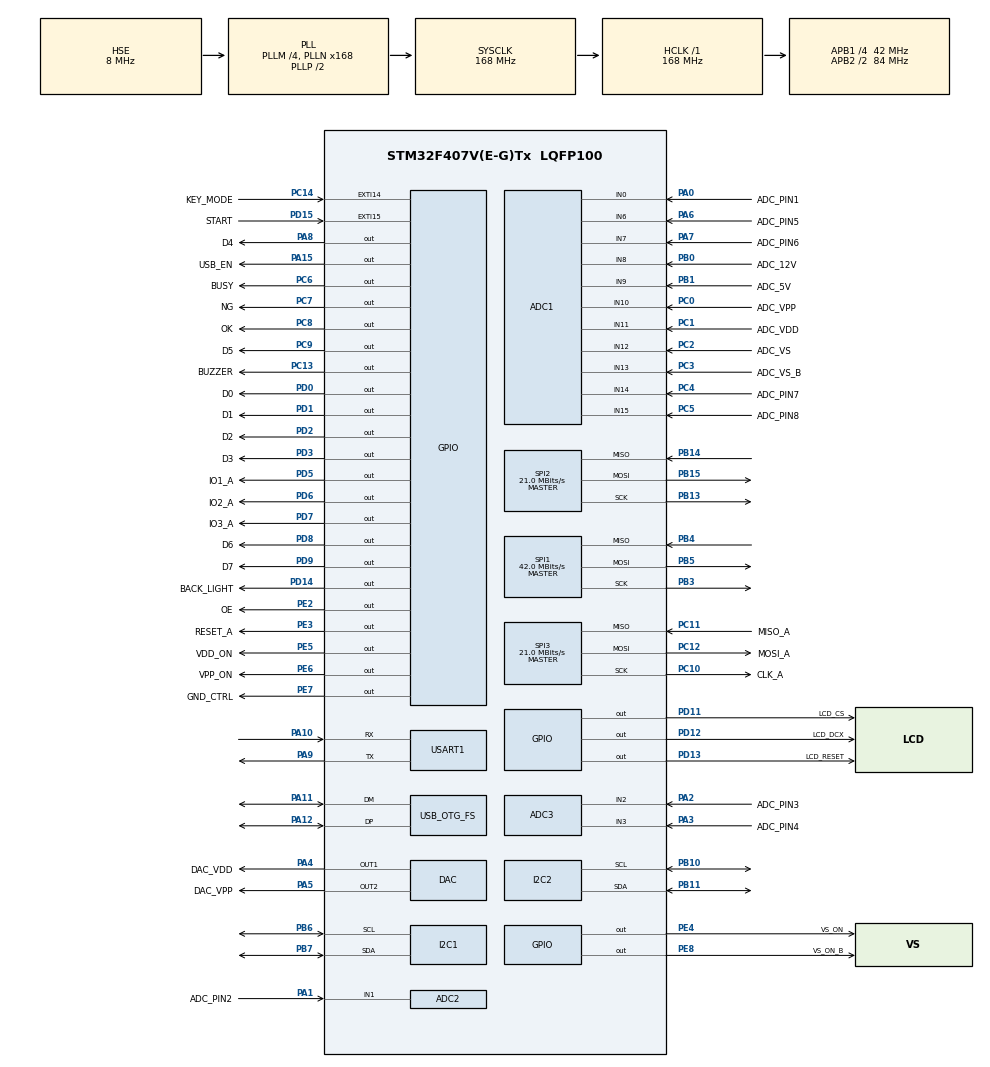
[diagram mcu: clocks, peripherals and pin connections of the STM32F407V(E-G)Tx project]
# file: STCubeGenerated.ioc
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ADC1.Channel-0\#ChannelRegularConversion=ADC_CHANNEL_0
ADC1.NbrOfConversionFlag=1
ADC1.Rank-0\#ChannelRegularConversion=1
ADC1.SamplingTime-0\#ChannelRegularConversion=ADC_SAMPLETIME_3CYCLES
ADC1.master=1
ADC2.Channel-0\#ChannelRegularConversion=ADC_CHANNEL_1
ADC2.NbrOfConversionFlag=1
ADC2.Rank-0\#ChannelRegularConversion=1
ADC2.SamplingTime-0\#ChannelRegularConversion=ADC_SAMPLETIME_3CYCLES
ADC3.Channel-0\#ChannelRegularConversion=ADC_CHANNEL_2
ADC3.NbrOfConversionFlag=1
ADC3.Rank-0\#ChannelRegularConversion=1
ADC3.SamplingTime-0\#ChannelRegularConversion=ADC_SAMPLETIME_3CYCLES
Mcu.Family=STM32F4
Mcu.Name=STM32F407V(E-G)Tx
Mcu.Package=LQFP100
NVIC.EXTI15_10_IRQn=true\:0\:0\:false\:false\:true\:true
NVIC.PriorityGroup=NVIC_PRIORITYGROUP_4
PA0-WKUP.GPIO_Label=ADC_PIN1
PA0-WKUP.Signal=ADCx_IN0
PA1.GPIO_Label=ADC_PIN2
PA1.Signal=ADCx_IN1
PA10.Mode=Asynchronous
PA10.Signal=USART1_RX
PA11.Mode=Device_Only
PA11.Signal=USB_OTG_FS_DM
PA12.Mode=Device_Only
PA12.Signal=USB_OTG_FS_DP
PA15.GPIO_Label=USB_EN
PA15.GPIO_PuPd=GPIO_PULLUP
PA15.PinState=GPIO_PIN_SET
PA15.Signal=GPIO_Output
PA2.GPIO_Label=ADC_PIN3
PA2.Signal=ADCx_IN2
PA3.GPIO_Label=ADC_PIN4
PA3.Signal=ADCx_IN3
PA4.GPIO_Label=DAC_VDD
PA4.Signal=COMP_DAC1_group
PA5.GPIO_Label=DAC_VPP
PA5.Signal=COMP_DAC2_group
PA6.GPIO_Label=ADC_PIN5
PA6.Signal=ADCx_IN6
PA7.GPIO_Label=ADC_PIN6
PA7.Signal=ADCx_IN7
PA8.GPIO_Label=D4
PA8.GPIO_PuPd=GPIO_PULLUP
PA8.Signal=GPIO_Output
PA9.Mode=Asynchronous
PA9.Signal=USART1_TX
PB0.GPIO_Label=ADC_12V
PB0.Signal=ADCx_IN8
PB1.GPIO_Label=ADC_5V
PB1.Signal=ADCx_IN9
PB10.Mode=I2C
PB10.Signal=I2C2_SCL
PB11.Mode=I2C
PB11.Signal=I2C2_SDA
PB12.Signal=SPI2_NSS
PB13.GPIO_PuPd=GPIO_NOPULL
PB13.Mode=Full_Duplex_Master
PB13.Signal=SPI2_SCK
PB14.Mode=Full_Duplex_Master
PB14.Signal=SPI2_MISO
PB15.GPIO_PuPd=GPIO_PULLUP
PB15.Mode=Full_Duplex_Master
PB15.Signal=SPI2_MOSI
PB3.Mode=Full_Duplex_Master
PB3.Signal=SPI1_SCK
PB4.Mode=Full_Duplex_Master
PB4.Signal=SPI1_MISO
PB5.Mode=Full_Duplex_Master
PB5.Signal=SPI1_MOSI
PB6.Mode=I2C
PB6.Signal=I2C1_SCL
PB7.Mode=I2C
PB7.Signal=I2C1_SDA
PC0.GPIO_Label=ADC_VPP
PC0.Signal=ADCx_IN10
PC1.GPIO_Label=ADC_VDD
PC1.Signal=ADCx_IN11
PC10.GPIO_Label=CLK_A
PC10.Mode=Full_Duplex_Master
PC10.Signal=SPI3_SCK
PC11.GPIO_Label=MISO_A
PC11.Mode=Full_Duplex_Master
PC11.Signal=SPI3_MISO
PC12.GPIO_Label=MOSI_A
PC12.Mode=Full_Duplex_Master
PC12.Signal=SPI3_MOSI
PC13-ANTI_TAMP.GPIO_Label=BUZZER
PC13-ANTI_TAMP.GPIO_PuPd=GPIO_PULLUP
PC13-ANTI_TAMP.Signal=GPIO_Output
PC14-OSC32_IN.GPIO_Label=KEY_MODE
PC14-OSC32_IN.GPIO_ModeDefaultEXTI=GPIO_MODE_IT_RISING_FALLING
PC14-OSC32_IN.GPIO_PuPd=GPIO_PULLDOWN
PC14-OSC32_IN.Signal=GPXTI14
PC2.GPIO_Label=ADC_VS
PC2.Signal=ADCx_IN12
PC3.GPIO_Label=ADC_VS_B
PC3.Signal=ADCx_IN13
PC4.GPIO_Label=ADC_PIN7
PC4.Signal=ADCx_IN14
PC5.GPIO_Label=ADC_PIN8
PC5.Signal=ADCx_IN15
PC6.GPIO_Label=BUSY
PC6.GPIO_PuPd=GPIO_PULLDOWN
PC6.Signal=GPIO_Output
PC7.GPIO_Label=NG
PC7.GPIO_PuPd=GPIO_PULLDOWN
PC7.Signal=GPIO_Output
PC8.GPIO_Label=OK
PC8.GPIO_PuPd=GPIO_PULLDOWN
PC8.Signal=GPIO_Output
PC9.GPIO_Label=D5
PC9.GPIO_PuPd=GPIO_PULLUP
PC9.Signal=GPIO_Output
PD0.GPIO_Label=D0
PD0.GPIO_PuPd=GPIO_PULLUP
PD0.Signal=GPIO_Output
PD1.GPIO_Label=D1
PD1.GPIO_PuPd=GPIO_PULLUP
PD1.Signal=GPIO_Output
PD11.GPIO_Label=LCD_CS
PD11.GPIO_PuPd=GPIO_PULLUP
PD11.PinState=GPIO_PIN_SET
PD11.Signal=GPIO_Output
PD12.GPIO_Label=LCD_DCX
PD12.GPIO_PuPd=GPIO_PULLUP
PD12.Signal=GPIO_Output
PD13.GPIO_Label=LCD_RESET
PD13.GPIO_PuPd=GPIO_PULLUP
PD13.PinState=GPIO_PIN_SET
PD13.Signal=GPIO_Output
PD14.GPIO_Label=BACK_LIGHT
PD14.GPIO_PuPd=GPIO_PULLUP
PD14.Signal=GPIO_Output
PD15.GPIO_Label=START
PD15.GPIO_ModeDefaultEXTI=GPIO_MODE_IT_RISING_FALLING
PD15.GPIO_PuPd=GPIO_PULLUP
PD15.Signal=GPXTI15
PD2.GPIO_Label=D2
PD2.GPIO_PuPd=GPIO_PULLUP
PD2.Signal=GPIO_Output
PD3.GPIO_Label=D3
PD3.GPIO_PuPd=GPIO_PULLUP
PD3.Signal=GPIO_Output
PD5.GPIO_Label=IO1_A
PD5.GPIO_PuPd=GPIO_PULLUP
PD5.Signal=GPIO_Output
PD6.GPIO_Label=IO2_A
PD6.GPIO_PuPd=GPIO_PULLUP
PD6.Signal=GPIO_Output
PD7.GPIO_Label=IO3_A
PD7.GPIO_PuPd=GPIO_PULLUP
PD7.Signal=GPIO_Output
PD8.GPIO_Label=D6
PD8.GPIO_PuPd=GPIO_PULLUP
PD8.Signal=GPIO_Output
PD9.GPIO_Label=D7
PD9.GPIO_PuPd=GPIO_PULLUP
PD9.Signal=GPIO_Output
PE2.GPIO_Label=OE
PE2.GPIO_PuPd=GPIO_PULLUP
PE2.Signal=GPIO_Output
PE3.GPIO_Label=RESET_A
PE3.GPIO_PuPd=GPIO_PULLUP
PE3.Signal=GPIO_Output
PE4.GPIO_Label=VS_ON
PE4.GPIO_PuPd=GPIO_PULLUP
PE4.Signal=GPIO_Output
PE5.GPIO_Label=VDD_ON
PE5.GPIO_PuPd=GPIO_PULLUP
PE5.Signal=GPIO_Output
PE6.GPIO_Label=VPP_ON
PE6.GPIO_PuPd=GPIO_PULLUP
PE6.Signal=GPIO_Output
PE7.GPIO_Label=GND_CTRL
PE7.GPIO_PuPd=GPIO_PULLUP
PE7.GPIO_Speed=GPIO_SPEED_FREQ_LOW
PE7.PinState=GPIO_PIN_SET
PE7.Signal=GPIO_Output
PE8.GPIO_Label=VS_ON_B
PE8.GPIO_PuPd=GPIO_PULLUP
PE8.Signal=GPIO_Output
PH0-OSC_IN.Mode=HSE-External-Oscillator
PH0-OSC_IN.Signal=RCC_OSC_IN
PH1-OSC_OUT.Mode=HSE-External-Oscillator
PH1-OSC_OUT.Signal=RCC_OSC_OUT
ProjectManager.HeapSize=0x8000
ProjectManager.StackSize=0x8000
ProjectManager.TargetToolchain=MDK-ARM V5
RCC.48MHZClocksFreq_Value=48000000
RCC.AHBFreq_Value=168000000
RCC.APB1CLKDivider=RCC_HCLK_DIV4
RCC.APB1Freq_Value=42000000
RCC.APB1TimFreq_Value=84000000
RCC.APB2CLKDivider=RCC_HCLK_DIV2
RCC.APB2Freq_Value=84000000
RCC.APB2TimFreq_Value=168000000
RCC.CortexFreq_Value=168000000
RCC.HCLKFreq_Value=168000000
RCC.HSE_VALUE=8000000
RCC.HSI_VALUE=16000000
RCC.LSE_VALUE=32768
RCC.PLLM=4
RCC.PLLN=168
RCC.PLLQ=7
RCC.SYSCLKFreq_VALUE=168000000
RCC.SYSCLKSource=RCC_SYSCLKSOURCE_PLLCLK
RCC.VCOOutputFreq_Value=336000000
SH.ADCx_IN0.0=ADC1_IN0,IN0
SH.ADCx_IN1.0=ADC2_IN1,IN1
SH.ADCx_IN10.0=ADC1_IN10,IN10
SH.ADCx_IN11.0=ADC1_IN11,IN11
SH.ADCx_IN12.0=ADC1_IN12,IN12
SH.ADCx_IN13.0=ADC1_IN13,IN13
SH.ADCx_IN14.0=ADC1_IN14,IN14
SH.ADCx_IN15.0=ADC1_IN15,IN15
SH.ADCx_IN2.0=ADC3_IN2,IN2
SH.ADCx_IN3.0=ADC3_IN3,IN3
SH.ADCx_IN6.0=ADC1_IN6,IN6
SH.ADCx_IN7.0=ADC1_IN7,IN7
SH.ADCx_IN8.0=ADC1_IN8,IN8
SH.ADCx_IN9.0=ADC1_IN9,IN9
SH.COMP_DAC1_group.0=DAC_OUT1,DAC_OUT1
SH.COMP_DAC2_group.0=DAC_OUT2,DAC_OUT2
SPI1.CalculateBaudRate=42.0 MBits/s
SPI1.Direction=SPI_DIRECTION_2LINES
SPI1.Mode=SPI_MODE_MASTER
SPI1.VirtualType=VM_MASTER
SPI2.CalculateBaudRate=21.0 MBits/s
SPI2.Direction=SPI_DIRECTION_2LINES
SPI2.Mode=SPI_MODE_MASTER
SPI2.VirtualType=VM_MASTER
SPI3.CalculateBaudRate=21.0 MBits/s
SPI3.Direction=SPI_DIRECTION_2LINES
SPI3.Mode=SPI_MODE_MASTER
SPI3.VirtualType=VM_MASTER
TIM13.ClockDivision=TIM_CLOCKDIVISION_DIV1
TIM13.Prescaler=0xa410
TIM6.Prescaler=0x54
TIM7.Prescaler=0x54
USART1.VirtualMode=VM_ASYNC
USB_OTG_FS.VirtualMode=Device_Only
VP_CRC_VS_CRC.Mode=CRC_Activate
VP_TIM10_VS_ClockSourceINT.Mode=Enable_Timer
VP_TIM13_VS_ClockSourceINT.Mode=Enable_Timer
VP_TIM14_VS_ClockSourceINT.Mode=Enable_Timer
VP_TIM6_VS_ClockSourceINT.Mode=Enable_Timer
VP_TIM7_VS_ClockSourceINT.Mode=Enable_Timer
board=custom

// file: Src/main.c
/**
  ******************************************************************************
  * @file           : main.c
  * @brief          : Main program body
  ******************************************************************************
  ** This notice applies to any and all portions of this file
  * that are not between comment pairs USER CODE BEGIN and
  * USER CODE END. Other portions of this file, whether
  * inserted by the user or by software development tools
  * are owned by their respective copyright owners.
  *
  * COPYRIGHT(c) 2019 STMicroelectronics
  *
  * Redistribution and use in source and binary forms, with or without modification,
  * are permitted provided that the following conditions are met:
  *   1. Redistributions of source code must retain the above copyright notice,
  *      this list of conditions and the following disclaimer.
  *   2. Redistributions in binary form must reproduce the above copyright notice,
  *      this list of conditions and the following disclaimer in the documentation
  *      and/or other materials provided with the distribution.
  *   3. Neither the name of STMicroelectronics nor the names of its contributors
  *      may be used to endorse or promote products derived from this software
  *      without specific prior written permission.
  *
  * THIS SOFTWARE IS PROVIDED BY THE COPYRIGHT HOLDERS AND CONTRIBUTORS "AS IS"
  * AND ANY EXPRESS OR IMPLIED WARRANTIES, INCLUDING, BUT NOT LIMITED TO, THE
  * IMPLIED WARRANTIES OF MERCHANTABILITY AND FITNESS FOR A PARTICULAR PURPOSE ARE
  * DISCLAIMED. IN NO EVENT SHALL THE COPYRIGHT HOLDER OR CONTRIBUTORS BE LIABLE
  * FOR ANY DIRECT, INDIRECT, INCIDENTAL, SPECIAL, EXEMPLARY, OR CONSEQUENTIAL
  * DAMAGES (INCLUDING, BUT NOT LIMITED TO, PROCUREMENT OF SUBSTITUTE GOODS OR
  * SERVICES; LOSS OF USE, DATA, OR PROFITS; OR BUSINESS INTERRUPTION) HOWEVER
  * CAUSED AND ON ANY THEORY OF LIABILITY, WHETHER IN CONTRACT, STRICT LIABILITY,
  * OR TORT (INCLUDING NEGLIGENCE OR OTHERWISE) ARISING IN ANY WAY OUT OF THE USE
  * OF THIS SOFTWARE, EVEN IF ADVISED OF THE POSSIBILITY OF SUCH DAMAGE.
  *
  ******************************************************************************
  */
#include "main.h"
#include "stm32f4xx_hal.h"

/* USER CODE BEGIN Includes */
#include "bootloader.h"
/* USER CODE END Includes */

ADC_HandleTypeDef hadc1;
ADC_HandleTypeDef hadc2;
ADC_HandleTypeDef hadc3;

CRC_HandleTypeDef hcrc;

DAC_HandleTypeDef hdac;

I2C_HandleTypeDef hi2c1;
I2C_HandleTypeDef hi2c2;

SPI_HandleTypeDef hspi1;
SPI_HandleTypeDef hspi2;
SPI_HandleTypeDef hspi3;

TIM_HandleTypeDef htim6;
TIM_HandleTypeDef htim7;
TIM_HandleTypeDef htim10;
TIM_HandleTypeDef htim13;
TIM_HandleTypeDef htim14;

UART_HandleTypeDef huart1;

PCD_HandleTypeDef hpcd_USB_OTG_FS;

/* USER CODE BEGIN PV */
/* Private variables ---------------------------------------------------------*/

/* USER CODE END PV */

void SystemClock_Config(void);
static void MX_GPIO_Init(void);
static void MX_USB_OTG_FS_PCD_Init(void);
static void MX_USART1_UART_Init(void);
static void MX_ADC1_Init(void);
static void MX_ADC2_Init(void);
static void MX_ADC3_Init(void);
static void MX_DAC_Init(void);
static void MX_CRC_Init(void);
static void MX_SPI2_Init(void);
static void MX_I2C2_Init(void);
static void MX_I2C1_Init(void);
static void MX_SPI1_Init(void);
static void MX_SPI3_Init(void);
static void MX_TIM6_Init(void);
static void MX_TIM7_Init(void);
static void MX_TIM10_Init(void);
static void MX_TIM13_Init(void);
static void MX_TIM14_Init(void);

/* USER CODE BEGIN PFP */
/* Private function prototypes -----------------------------------------------*/

/* USER CODE END PFP */

int main(void)
{

  /* MCU Configuration----------------------------------------------------------*/

  /* Reset of all peripherals, Initializes the Flash interface and the Systick. */
  HAL_Init();

  /* Configure the system clock */
  SystemClock_Config();

  /* Initialize all configured peripherals */
  MX_GPIO_Init();
  MX_USB_OTG_FS_PCD_Init();
  MX_USART1_UART_Init();
  MX_ADC1_Init();
  MX_ADC2_Init();
  MX_ADC3_Init();
  MX_DAC_Init();
  MX_CRC_Init();
  MX_SPI2_Init();
  MX_I2C2_Init();
  MX_I2C1_Init();
  MX_SPI1_Init();
  MX_SPI3_Init();
  MX_TIM6_Init();
  MX_TIM7_Init();
  MX_TIM10_Init();
  MX_TIM13_Init();
  MX_TIM14_Init();
  /* USER CODE BEGIN 2 */
	osStart();
  /* USER CODE END 2 */

  /* Infinite loop */
  while (1)
  {

  }

}

void SystemClock_Config(void)
{

  RCC_OscInitTypeDef RCC_OscInitStruct;
  RCC_ClkInitTypeDef RCC_ClkInitStruct;

    /**Configure the main internal regulator output voltage
    */
  __HAL_RCC_PWR_CLK_ENABLE();

  __HAL_PWR_VOLTAGESCALING_CONFIG(PWR_REGULATOR_VOLTAGE_SCALE1);

    /**Initializes the CPU, AHB and APB busses clocks
    */
  RCC_OscInitStruct.OscillatorType = RCC_OSCILLATORTYPE_HSE;
  RCC_OscInitStruct.HSEState = RCC_HSE_ON;
  RCC_OscInitStruct.PLL.PLLState = RCC_PLL_ON;
  RCC_OscInitStruct.PLL.PLLSource = RCC_PLLSOURCE_HSE;
  RCC_OscInitStruct.PLL.PLLM = 4;
  RCC_OscInitStruct.PLL.PLLN = 168;
  RCC_OscInitStruct.PLL.PLLP = RCC_PLLP_DIV2;
  RCC_OscInitStruct.PLL.PLLQ = 7;
  if (HAL_RCC_OscConfig(&RCC_OscInitStruct) != HAL_OK)
  {
    _Error_Handler(__FILE__, __LINE__);
  }

    /**Initializes the CPU, AHB and APB busses clocks
    */
  RCC_ClkInitStruct.ClockType = RCC_CLOCKTYPE_HCLK|RCC_CLOCKTYPE_SYSCLK
                              |RCC_CLOCKTYPE_PCLK1|RCC_CLOCKTYPE_PCLK2;
  RCC_ClkInitStruct.SYSCLKSource = RCC_SYSCLKSOURCE_PLLCLK;
  RCC_ClkInitStruct.AHBCLKDivider = RCC_SYSCLK_DIV1;
  RCC_ClkInitStruct.APB1CLKDivider = RCC_HCLK_DIV4;
  RCC_ClkInitStruct.APB2CLKDivider = RCC_HCLK_DIV2;

  if (HAL_RCC_ClockConfig(&RCC_ClkInitStruct, FLASH_LATENCY_5) != HAL_OK)
  {
    _Error_Handler(__FILE__, __LINE__);
  }

    /**Configure the Systick interrupt time
    */
  HAL_SYSTICK_Config(HAL_RCC_GetHCLKFreq()/1000);

    /**Configure the Systick
    */
  HAL_SYSTICK_CLKSourceConfig(SYSTICK_CLKSOURCE_HCLK);

  /* SysTick_IRQn interrupt configuration */
  HAL_NVIC_SetPriority(SysTick_IRQn, 0, 0);
}

/* ADC1 init function */
static void MX_ADC1_Init(void)
{

  ADC_ChannelConfTypeDef sConfig;

    /**Configure the global features of the ADC (Clock, Resolution, Data Alignment and number of conversion)
    */
  hadc1.Instance = ADC1;
  hadc1.Init.ClockPrescaler = ADC_CLOCK_SYNC_PCLK_DIV4;
  hadc1.Init.Resolution = ADC_RESOLUTION_12B;
  hadc1.Init.ScanConvMode = DISABLE;
  hadc1.Init.ContinuousConvMode = DISABLE;
  hadc1.Init.DiscontinuousConvMode = DISABLE;
  hadc1.Init.ExternalTrigConvEdge = ADC_EXTERNALTRIGCONVEDGE_NONE;
  hadc1.Init.ExternalTrigConv = ADC_SOFTWARE_START;
  hadc1.Init.DataAlign = ADC_DATAALIGN_RIGHT;
  hadc1.Init.NbrOfConversion = 1;
  hadc1.Init.DMAContinuousRequests = DISABLE;
  hadc1.Init.EOCSelection = ADC_EOC_SINGLE_CONV;
  if (HAL_ADC_Init(&hadc1) != HAL_OK)
  {
    _Error_Handler(__FILE__, __LINE__);
  }

    /**Configure for the selected ADC regular channel its corresponding rank in the sequencer and its sample time.
    */
  sConfig.Channel = ADC_CHANNEL_0;
  sConfig.Rank = 1;
  sConfig.SamplingTime = ADC_SAMPLETIME_3CYCLES;
  if (HAL_ADC_ConfigChannel(&hadc1, &sConfig) != HAL_OK)
  {
    _Error_Handler(__FILE__, __LINE__);
  }

}

/* ADC2 init function */
static void MX_ADC2_Init(void)
{

  ADC_ChannelConfTypeDef sConfig;

    /**Configure the global features of the ADC (Clock, Resolution, Data Alignment and number of conversion)
    */
  hadc2.Instance = ADC2;
  hadc2.Init.ClockPrescaler = ADC_CLOCK_SYNC_PCLK_DIV4;
  hadc2.Init.Resolution = ADC_RESOLUTION_12B;
  hadc2.Init.ScanConvMode = DISABLE;
  hadc2.Init.ContinuousConvMode = DISABLE;
  hadc2.Init.DiscontinuousConvMode = DISABLE;
  hadc2.Init.ExternalTrigConvEdge = ADC_EXTERNALTRIGCONVEDGE_NONE;
  hadc2.Init.ExternalTrigConv = ADC_SOFTWARE_START;
  hadc2.Init.DataAlign = ADC_DATAALIGN_RIGHT;
  hadc2.Init.NbrOfConversion = 1;
  hadc2.Init.DMAContinuousRequests = DISABLE;
  hadc2.Init.EOCSelection = ADC_EOC_SINGLE_CONV;
  if (HAL_ADC_Init(&hadc2) != HAL_OK)
  {
    _Error_Handler(__FILE__, __LINE__);
  }

    /**Configure for the selected ADC regular channel its corresponding rank in the sequencer and its sample time.
    */
  sConfig.Channel = ADC_CHANNEL_1;
  sConfig.Rank = 1;
  sConfig.SamplingTime = ADC_SAMPLETIME_3CYCLES;
  if (HAL_ADC_ConfigChannel(&hadc2, &sConfig) != HAL_OK)
  {
    _Error_Handler(__FILE__, __LINE__);
  }

}

/* ADC3 init function */
static void MX_ADC3_Init(void)
{

  ADC_ChannelConfTypeDef sConfig;

    /**Configure the global features of the ADC (Clock, Resolution, Data Alignment and number of conversion)
    */
  hadc3.Instance = ADC3;
  hadc3.Init.ClockPrescaler = ADC_CLOCK_SYNC_PCLK_DIV4;
  hadc3.Init.Resolution = ADC_RESOLUTION_12B;
  hadc3.Init.ScanConvMode = DISABLE;
  hadc3.Init.ContinuousConvMode = DISABLE;
  hadc3.Init.DiscontinuousConvMode = DISABLE;
  hadc3.Init.ExternalTrigConvEdge = ADC_EXTERNALTRIGCONVEDGE_NONE;
  hadc3.Init.ExternalTrigConv = ADC_SOFTWARE_START;
  hadc3.Init.DataAlign = ADC_DATAALIGN_RIGHT;
  hadc3.Init.NbrOfConversion = 1;
  hadc3.Init.DMAContinuousRequests = DISABLE;
  hadc3.Init.EOCSelection = ADC_EOC_SINGLE_CONV;
  if (HAL_ADC_Init(&hadc3) != HAL_OK)
  {
    _Error_Handler(__FILE__, __LINE__);
  }

    /**Configure for the selected ADC regular channel its corresponding rank in the sequencer and its sample time.
    */
  sConfig.Channel = ADC_CHANNEL_2;
  sConfig.Rank = 1;
  sConfig.SamplingTime = ADC_SAMPLETIME_3CYCLES;
  if (HAL_ADC_ConfigChannel(&hadc3, &sConfig) != HAL_OK)
  {
    _Error_Handler(__FILE__, __LINE__);
  }

}

/* CRC init function */
static void MX_CRC_Init(void)
{

  hcrc.Instance = CRC;
  if (HAL_CRC_Init(&hcrc) != HAL_OK)
  {
    _Error_Handler(__FILE__, __LINE__);
  }

}

/* DAC init function */
static void MX_DAC_Init(void)
{

  DAC_ChannelConfTypeDef sConfig;

    /**DAC Initialization
    */
  hdac.Instance = DAC;
  if (HAL_DAC_Init(&hdac) != HAL_OK)
  {
    _Error_Handler(__FILE__, __LINE__);
  }

    /**DAC channel OUT1 config
    */
  sConfig.DAC_Trigger = DAC_TRIGGER_NONE;
  sConfig.DAC_OutputBuffer = DAC_OUTPUTBUFFER_ENABLE;
  if (HAL_DAC_ConfigChannel(&hdac, &sConfig, DAC_CHANNEL_1) != HAL_OK)
  {
    _Error_Handler(__FILE__, __LINE__);
  }

    /**DAC channel OUT2 config
    */
  if (HAL_DAC_ConfigChannel(&hdac, &sConfig, DAC_CHANNEL_2) != HAL_OK)
  {
    _Error_Handler(__FILE__, __LINE__);
  }

}

/* I2C1 init function */
static void MX_I2C1_Init(void)
{

  hi2c1.Instance = I2C1;
  hi2c1.Init.ClockSpeed = 100000;
  hi2c1.Init.DutyCycle = I2C_DUTYCYCLE_2;
  hi2c1.Init.OwnAddress1 = 0;
  hi2c1.Init.AddressingMode = I2C_ADDRESSINGMODE_7BIT;
  hi2c1.Init.DualAddressMode = I2C_DUALADDRESS_DISABLE;
  hi2c1.Init.OwnAddress2 = 0;
  hi2c1.Init.GeneralCallMode = I2C_GENERALCALL_DISABLE;
  hi2c1.Init.NoStretchMode = I2C_NOSTRETCH_DISABLE;
  if (HAL_I2C_Init(&hi2c1) != HAL_OK)
  {
    _Error_Handler(__FILE__, __LINE__);
  }

}

/* I2C2 init function */
static void MX_I2C2_Init(void)
{

  hi2c2.Instance = I2C2;
  hi2c2.Init.ClockSpeed = 100000;
  hi2c2.Init.DutyCycle = I2C_DUTYCYCLE_2;
  hi2c2.Init.OwnAddress1 = 0;
  hi2c2.Init.AddressingMode = I2C_ADDRESSINGMODE_7BIT;
  hi2c2.Init.DualAddressMode = I2C_DUALADDRESS_DISABLE;
  hi2c2.Init.OwnAddress2 = 0;
  hi2c2.Init.GeneralCallMode = I2C_GENERALCALL_DISABLE;
  hi2c2.Init.NoStretchMode = I2C_NOSTRETCH_DISABLE;
  if (HAL_I2C_Init(&hi2c2) != HAL_OK)
  {
    _Error_Handler(__FILE__, __LINE__);
  }

}

/* SPI1 init function */
static void MX_SPI1_Init(void)
{

  /* SPI1 parameter configuration*/
  hspi1.Instance = SPI1;
  hspi1.Init.Mode = SPI_MODE_MASTER;
  hspi1.Init.Direction = SPI_DIRECTION_2LINES;
  hspi1.Init.DataSize = SPI_DATASIZE_8BIT;
  hspi1.Init.CLKPolarity = SPI_POLARITY_LOW;
  hspi1.Init.CLKPhase = SPI_PHASE_1EDGE;
  hspi1.Init.NSS = SPI_NSS_SOFT;
  hspi1.Init.BaudRatePrescaler = SPI_BAUDRATEPRESCALER_2;
  hspi1.Init.FirstBit = SPI_FIRSTBIT_MSB;
  hspi1.Init.TIMode = SPI_TIMODE_DISABLE;
  hspi1.Init.CRCCalculation = SPI_CRCCALCULATION_DISABLE;
  hspi1.Init.CRCPolynomial = 10;
  if (HAL_SPI_Init(&hspi1) != HAL_OK)
  {
    _Error_Handler(__FILE__, __LINE__);
  }

}

/* SPI2 init function */
static void MX_SPI2_Init(void)
{

  /* SPI2 parameter configuration*/
  hspi2.Instance = SPI2;
  hspi2.Init.Mode = SPI_MODE_MASTER;
  hspi2.Init.Direction = SPI_DIRECTION_2LINES;
  hspi2.Init.DataSize = SPI_DATASIZE_8BIT;
  hspi2.Init.CLKPolarity = SPI_POLARITY_LOW;
  hspi2.Init.CLKPhase = SPI_PHASE_1EDGE;
  hspi2.Init.NSS = SPI_NSS_SOFT;
  hspi2.Init.BaudRatePrescaler = SPI_BAUDRATEPRESCALER_2;
  hspi2.Init.FirstBit = SPI_FIRSTBIT_MSB;
  hspi2.Init.TIMode = SPI_TIMODE_DISABLE;
  hspi2.Init.CRCCalculation = SPI_CRCCALCULATION_DISABLE;
  hspi2.Init.CRCPolynomial = 10;
  if (HAL_SPI_Init(&hspi2) != HAL_OK)
  {
    _Error_Handler(__FILE__, __LINE__);
  }

}

/* SPI3 init function */
static void MX_SPI3_Init(void)
{

  /* SPI3 parameter configuration*/
  hspi3.Instance = SPI3;
  hspi3.Init.Mode = SPI_MODE_MASTER;
  hspi3.Init.Direction = SPI_DIRECTION_2LINES;
  hspi3.Init.DataSize = SPI_DATASIZE_8BIT;
  hspi3.Init.CLKPolarity = SPI_POLARITY_LOW;
  hspi3.Init.CLKPhase = SPI_PHASE_1EDGE;
  hspi3.Init.NSS = SPI_NSS_SOFT;
  hspi3.Init.BaudRatePrescaler = SPI_BAUDRATEPRESCALER_2;
  hspi3.Init.FirstBit = SPI_FIRSTBIT_MSB;
  hspi3.Init.TIMode = SPI_TIMODE_DISABLE;
  hspi3.Init.CRCCalculation = SPI_CRCCALCULATION_DISABLE;
  hspi3.Init.CRCPolynomial = 10;
  if (HAL_SPI_Init(&hspi3) != HAL_OK)
  {
    _Error_Handler(__FILE__, __LINE__);
  }

}

/* TIM6 init function */
static void MX_TIM6_Init(void)
{

  TIM_MasterConfigTypeDef sMasterConfig;

  htim6.Instance = TIM6;
  htim6.Init.Prescaler = 0x54;
  htim6.Init.CounterMode = TIM_COUNTERMODE_UP;
  htim6.Init.Period = 0;
  if (HAL_TIM_Base_Init(&htim6) != HAL_OK)
  {
    _Error_Handler(__FILE__, __LINE__);
  }

  sMasterConfig.MasterOutputTrigger = TIM_TRGO_RESET;
  sMasterConfig.MasterSlaveMode = TIM_MASTERSLAVEMODE_DISABLE;
  if (HAL_TIMEx_MasterConfigSynchronization(&htim6, &sMasterConfig) != HAL_OK)
  {
    _Error_Handler(__FILE__, __LINE__);
  }

}

/* TIM7 init function */
static void MX_TIM7_Init(void)
{

  TIM_MasterConfigTypeDef sMasterConfig;

  htim7.Instance = TIM7;
  htim7.Init.Prescaler = 0x54;
  htim7.Init.CounterMode = TIM_COUNTERMODE_UP;
  htim7.Init.Period = 0;
  if (HAL_TIM_Base_Init(&htim7) != HAL_OK)
  {
    _Error_Handler(__FILE__, __LINE__);
  }

  sMasterConfig.MasterOutputTrigger = TIM_TRGO_RESET;
  sMasterConfig.MasterSlaveMode = TIM_MASTERSLAVEMODE_DISABLE;
  if (HAL_TIMEx_MasterConfigSynchronization(&htim7, &sMasterConfig) != HAL_OK)
  {
    _Error_Handler(__FILE__, __LINE__);
  }

}

/* TIM10 init function */
static void MX_TIM10_Init(void)
{

  htim10.Instance = TIM10;
  htim10.Init.Prescaler = 0;
  htim10.Init.CounterMode = TIM_COUNTERMODE_UP;
  htim10.Init.Period = 0;
  htim10.Init.ClockDivision = TIM_CLOCKDIVISION_DIV1;
  if (HAL_TIM_Base_Init(&htim10) != HAL_OK)
  {
    _Error_Handler(__FILE__, __LINE__);
  }

}

/* TIM13 init function */
static void MX_TIM13_Init(void)
{

  htim13.Instance = TIM13;
  htim13.Init.Prescaler = 0xa410;
  htim13.Init.CounterMode = TIM_COUNTERMODE_UP;
  htim13.Init.Period = 0;
  htim13.Init.ClockDivision = TIM_CLOCKDIVISION_DIV1;
  if (HAL_TIM_Base_Init(&htim13) != HAL_OK)
  {
    _Error_Handler(__FILE__, __LINE__);
  }

}

/* TIM14 init function */
static void MX_TIM14_Init(void)
{

  htim14.Instance = TIM14;
  htim14.Init.Prescaler = 0;
  htim14.Init.CounterMode = TIM_COUNTERMODE_UP;
  htim14.Init.Period = 0;
  htim14.Init.ClockDivision = TIM_CLOCKDIVISION_DIV1;
  if (HAL_TIM_Base_Init(&htim14) != HAL_OK)
  {
    _Error_Handler(__FILE__, __LINE__);
  }

}

/* USART1 init function */
static void MX_USART1_UART_Init(void)
{

  huart1.Instance = USART1;
  huart1.Init.BaudRate = 115200;
  huart1.Init.WordLength = UART_WORDLENGTH_8B;
  huart1.Init.StopBits = UART_STOPBITS_1;
  huart1.Init.Parity = UART_PARITY_NONE;
  huart1.Init.Mode = UART_MODE_TX_RX;
  huart1.Init.HwFlowCtl = UART_HWCONTROL_NONE;
  huart1.Init.OverSampling = UART_OVERSAMPLING_16;
  if (HAL_UART_Init(&huart1) != HAL_OK)
  {
    _Error_Handler(__FILE__, __LINE__);
  }

}

/* USB_OTG_FS init function */
static void MX_USB_OTG_FS_PCD_Init(void)
{

  hpcd_USB_OTG_FS.Instance = USB_OTG_FS;
  hpcd_USB_OTG_FS.Init.dev_endpoints = 4;
  hpcd_USB_OTG_FS.Init.speed = PCD_SPEED_FULL;
  hpcd_USB_OTG_FS.Init.dma_enable = DISABLE;
  hpcd_USB_OTG_FS.Init.ep0_mps = DEP0CTL_MPS_64;
  hpcd_USB_OTG_FS.Init.phy_itface = PCD_PHY_EMBEDDED;
  hpcd_USB_OTG_FS.Init.Sof_enable = DISABLE;
  hpcd_USB_OTG_FS.Init.low_power_enable = DISABLE;
  hpcd_USB_OTG_FS.Init.lpm_enable = DISABLE;
  hpcd_USB_OTG_FS.Init.vbus_sensing_enable = DISABLE;
  hpcd_USB_OTG_FS.Init.use_dedicated_ep1 = DISABLE;
  if (HAL_PCD_Init(&hpcd_USB_OTG_FS) != HAL_OK)
  {
    _Error_Handler(__FILE__, __LINE__);
  }

}

/** Configure pins as
        * Analog
        * Input
        * Output
        * EVENT_OUT
        * EXTI
*/
static void MX_GPIO_Init(void)
{

  GPIO_InitTypeDef GPIO_InitStruct;

  /* GPIO Ports Clock Enable */
  __HAL_RCC_GPIOE_CLK_ENABLE();
  __HAL_RCC_GPIOC_CLK_ENABLE();
  __HAL_RCC_GPIOH_CLK_ENABLE();
  __HAL_RCC_GPIOA_CLK_ENABLE();
  __HAL_RCC_GPIOB_CLK_ENABLE();
  __HAL_RCC_GPIOD_CLK_ENABLE();

  /*Configure GPIO pin Output Level */
  HAL_GPIO_WritePin(GPIOE, OE_Pin|RESET_A_Pin|VS_ON_Pin|VDD_ON_Pin
                          |VPP_ON_Pin|VS_ON_B_Pin, GPIO_PIN_RESET);

  /*Configure GPIO pin Output Level */
  HAL_GPIO_WritePin(GPIOC, BUZZER_Pin|BUSY_Pin|NG_Pin|OK_Pin
                          |D5_Pin, GPIO_PIN_RESET);

  /*Configure GPIO pin Output Level */
  HAL_GPIO_WritePin(GND_CTRL_GPIO_Port, GND_CTRL_Pin, GPIO_PIN_SET);

  /*Configure GPIO pin Output Level */
  HAL_GPIO_WritePin(GPIOD, D6_Pin|D7_Pin|LCD_DCX_Pin|BACK_LIGHT_Pin
                          |D0_Pin|D1_Pin|D2_Pin|D3_Pin
                          |IO1_A_Pin|IO2_A_Pin|IO3_A_Pin, GPIO_PIN_RESET);

  /*Configure GPIO pin Output Level */
  HAL_GPIO_WritePin(GPIOD, LCD_CS_Pin|LCD_RESET_Pin, GPIO_PIN_SET);

  /*Configure GPIO pin Output Level */
  HAL_GPIO_WritePin(D4_GPIO_Port, D4_Pin, GPIO_PIN_RESET);

  /*Configure GPIO pin Output Level */
  HAL_GPIO_WritePin(USB_EN_GPIO_Port, USB_EN_Pin, GPIO_PIN_SET);

  /*Configure GPIO pins : OE_Pin RESET_A_Pin VS_ON_Pin VDD_ON_Pin
                           VPP_ON_Pin GND_CTRL_Pin VS_ON_B_Pin */
  GPIO_InitStruct.Pin = OE_Pin|RESET_A_Pin|VS_ON_Pin|VDD_ON_Pin
                          |VPP_ON_Pin|GND_CTRL_Pin|VS_ON_B_Pin;
  GPIO_InitStruct.Mode = GPIO_MODE_OUTPUT_PP;
  GPIO_InitStruct.Pull = GPIO_PULLUP;
  GPIO_InitStruct.Speed = GPIO_SPEED_FREQ_LOW;
  HAL_GPIO_Init(GPIOE, &GPIO_InitStruct);

  /*Configure GPIO pins : BUZZER_Pin D5_Pin */
  GPIO_InitStruct.Pin = BUZZER_Pin|D5_Pin;
  GPIO_InitStruct.Mode = GPIO_MODE_OUTPUT_PP;
  GPIO_InitStruct.Pull = GPIO_PULLUP;
  GPIO_InitStruct.Speed = GPIO_SPEED_FREQ_LOW;
  HAL_GPIO_Init(GPIOC, &GPIO_InitStruct);

  /*Configure GPIO pin : KEY_MODE_Pin */
  GPIO_InitStruct.Pin = KEY_MODE_Pin;
  GPIO_InitStruct.Mode = GPIO_MODE_IT_RISING_FALLING;
  GPIO_InitStruct.Pull = GPIO_PULLDOWN;
  HAL_GPIO_Init(KEY_MODE_GPIO_Port, &GPIO_InitStruct);

  /*Configure GPIO pins : D6_Pin D7_Pin LCD_CS_Pin LCD_DCX_Pin
                           LCD_RESET_Pin BACK_LIGHT_Pin D0_Pin D1_Pin
                           D2_Pin D3_Pin IO1_A_Pin IO2_A_Pin
                           IO3_A_Pin */
  GPIO_InitStruct.Pin = D6_Pin|D7_Pin|LCD_CS_Pin|LCD_DCX_Pin
                          |LCD_RESET_Pin|BACK_LIGHT_Pin|D0_Pin|D1_Pin
                          |D2_Pin|D3_Pin|IO1_A_Pin|IO2_A_Pin
                          |IO3_A_Pin;
  GPIO_InitStruct.Mode = GPIO_MODE_OUTPUT_PP;
  GPIO_InitStruct.Pull = GPIO_PULLUP;
  GPIO_InitStruct.Speed = GPIO_SPEED_FREQ_LOW;
  HAL_GPIO_Init(GPIOD, &GPIO_InitStruct);

  /*Configure GPIO pin : START_Pin */
  GPIO_InitStruct.Pin = START_Pin;
  GPIO_InitStruct.Mode = GPIO_MODE_IT_RISING_FALLING;
  GPIO_InitStruct.Pull = GPIO_PULLUP;
  HAL_GPIO_Init(START_GPIO_Port, &GPIO_InitStruct);

  /*Configure GPIO pins : BUSY_Pin NG_Pin OK_Pin */
  GPIO_InitStruct.Pin = BUSY_Pin|NG_Pin|OK_Pin;
  GPIO_InitStruct.Mode = GPIO_MODE_OUTPUT_PP;
  GPIO_InitStruct.Pull = GPIO_PULLDOWN;
  GPIO_InitStruct.Speed = GPIO_SPEED_FREQ_LOW;
  HAL_GPIO_Init(GPIOC, &GPIO_InitStruct);

  /*Configure GPIO pins : D4_Pin USB_EN_Pin */
  GPIO_InitStruct.Pin = D4_Pin|USB_EN_Pin;
  GPIO_InitStruct.Mode = GPIO_MODE_OUTPUT_PP;
  GPIO_InitStruct.Pull = GPIO_PULLUP;
  GPIO_InitStruct.Speed = GPIO_SPEED_FREQ_LOW;
  HAL_GPIO_Init(GPIOA, &GPIO_InitStruct);

  /* EXTI interrupt init*/
  HAL_NVIC_SetPriority(EXTI15_10_IRQn, 0, 0);
  HAL_NVIC_EnableIRQ(EXTI15_10_IRQn);

}

void _Error_Handler(char *file, int line)
{
  while(1)
  {
  }
}

/************************ (C) COPYRIGHT STMicroelectronics *****END OF FILE****/
